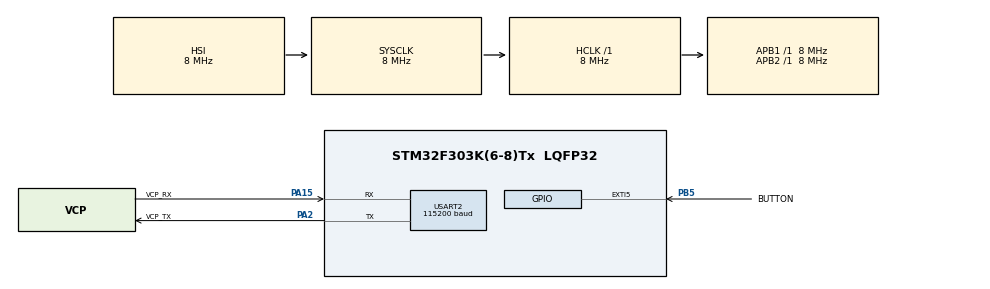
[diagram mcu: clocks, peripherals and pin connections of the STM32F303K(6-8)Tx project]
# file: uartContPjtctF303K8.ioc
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Mcu.Family=STM32F3
Mcu.Name=STM32F303K(6-8)Tx
Mcu.Package=LQFP32
NVIC.EXTI9_5_IRQn=true\:0\:0\:false\:false\:true\:true\:true\:true
NVIC.PriorityGroup=NVIC_PRIORITYGROUP_4
NVIC.USART2_IRQn=true\:0\:0\:false\:false\:true\:true\:true\:true
PA13.GPIO_Label=SWDIO
PA13.Signal=SYS_JTMS-SWDIO
PA14.GPIO_Label=SWCLK
PA14.Signal=SYS_JTCK-SWCLK
PA15.GPIO_Label=VCP_RX
PA15.Mode=Asynchronous
PA15.Signal=USART2_RX
PA2.GPIO_Label=VCP_TX
PA2.Mode=Asynchronous
PA2.Signal=USART2_TX
PB5.GPIO_Label=BUTTON
PB5.GPIO_ModeDefaultEXTI=GPIO_MODE_IT_FALLING
PB5.Signal=GPXTI5
PF0\ /\ OSC_IN.GPIO_Label=MCO
PF0\ /\ OSC_IN.Signal=RCC_OSC_IN
ProjectManager.HeapSize=0x200
ProjectManager.StackSize=0x400
ProjectManager.TargetToolchain=STM32CubeIDE
RCC.AHBFreq_Value=8000000
RCC.APB1Freq_Value=8000000
RCC.APB2Freq_Value=8000000
RCC.CortexFreq_Value=8000000
RCC.HSE_VALUE=8000000
RCC.HSI_VALUE=8000000
RCC.SYSCLKFreq_VALUE=8000000
USART2.BaudRate=115200
USART2.VirtualMode-Asynchronous=VM_ASYNC
board=NUCLEO-F303K8

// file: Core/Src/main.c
/* USER CODE BEGIN Header */
/**
  ******************************************************************************
  * @file           : main.c
  * @brief          : Main program body
  ******************************************************************************
  * @attention
  *
  * Copyright (c) 2025 STMicroelectronics.
  * All rights reserved.
  *
  * This software is licensed under terms that can be found in the LICENSE file
  * in the root directory of this software component.
  * If no LICENSE file comes with this software, it is provided AS-IS.
  *
  ******************************************************************************
  */
/* USER CODE END Header */
#include "main.h"

/* USER CODE BEGIN Includes */
#include <string.h>
/* USER CODE END Includes */

UART_HandleTypeDef huart2;

/* USER CODE BEGIN PV */
uint8_t c=1;
/* USER CODE END PV */

void SystemClock_Config(void);
static void MX_GPIO_Init(void);
static void MX_USART2_UART_Init(void);
/* USER CODE BEGIN PFP */
char* utoa(uint32_t value, char* buffer);
void printUtoa(uint32_t value);
void HAL_GPIO_EXTI_Callback(uint16_t GPIO_Pin);
/* USER CODE END PFP */

int main(void)
{

  /* MCU Configuration--------------------------------------------------------*/

  /* Reset of all peripherals, Initializes the Flash interface and the Systick. */
  HAL_Init();

  /* Configure the system clock */
  SystemClock_Config();

  /* Initialize all configured peripherals */
  MX_GPIO_Init();
  MX_USART2_UART_Init();

  /* Infinite loop */
  /* USER CODE BEGIN WHILE */
  while (1)
  {
	  while(c<=10){
		  printUtoa(c);
		  HAL_UART_Transmit(&huart2, (uint8_t*) "\n", 1, HAL_MAX_DELAY);
		  HAL_Delay(500);
	  }
	  c=1;

	  /* USER CODE END WHILE */

  }
}

void SystemClock_Config(void)
{
  RCC_OscInitTypeDef RCC_OscInitStruct = {0};
  RCC_ClkInitTypeDef RCC_ClkInitStruct = {0};

  /** Initializes the RCC Oscillators according to the specified parameters
  * in the RCC_OscInitTypeDef structure.
  */
  RCC_OscInitStruct.OscillatorType = RCC_OSCILLATORTYPE_HSI;
  RCC_OscInitStruct.HSIState = RCC_HSI_ON;
  RCC_OscInitStruct.HSICalibrationValue = RCC_HSICALIBRATION_DEFAULT;
  RCC_OscInitStruct.PLL.PLLState = RCC_PLL_NONE;
  if (HAL_RCC_OscConfig(&RCC_OscInitStruct) != HAL_OK)
  {
    Error_Handler();
  }

  /** Initializes the CPU, AHB and APB buses clocks
  */
  RCC_ClkInitStruct.ClockType = RCC_CLOCKTYPE_HCLK|RCC_CLOCKTYPE_SYSCLK
                              |RCC_CLOCKTYPE_PCLK1|RCC_CLOCKTYPE_PCLK2;
  RCC_ClkInitStruct.SYSCLKSource = RCC_SYSCLKSOURCE_HSI;
  RCC_ClkInitStruct.AHBCLKDivider = RCC_SYSCLK_DIV1;
  RCC_ClkInitStruct.APB1CLKDivider = RCC_HCLK_DIV1;
  RCC_ClkInitStruct.APB2CLKDivider = RCC_HCLK_DIV1;

  if (HAL_RCC_ClockConfig(&RCC_ClkInitStruct, FLASH_LATENCY_0) != HAL_OK)
  {
    Error_Handler();
  }
}

static void MX_USART2_UART_Init(void)
{

  huart2.Instance = USART2;
  huart2.Init.BaudRate = 115200;
  huart2.Init.WordLength = UART_WORDLENGTH_8B;
  huart2.Init.StopBits = UART_STOPBITS_1;
  huart2.Init.Parity = UART_PARITY_NONE;
  huart2.Init.Mode = UART_MODE_TX_RX;
  huart2.Init.HwFlowCtl = UART_HWCONTROL_NONE;
  huart2.Init.OverSampling = UART_OVERSAMPLING_16;
  huart2.Init.OneBitSampling = UART_ONE_BIT_SAMPLE_DISABLE;
  huart2.AdvancedInit.AdvFeatureInit = UART_ADVFEATURE_NO_INIT;
  if (HAL_UART_Init(&huart2) != HAL_OK)
  {
    Error_Handler();
  }

}

static void MX_GPIO_Init(void)
{
  GPIO_InitTypeDef GPIO_InitStruct = {0};

  /* GPIO Ports Clock Enable */
  __HAL_RCC_GPIOF_CLK_ENABLE();
  __HAL_RCC_GPIOA_CLK_ENABLE();
  __HAL_RCC_GPIOB_CLK_ENABLE();

  /*Configure GPIO pin : BUTTON_Pin */
  GPIO_InitStruct.Pin = BUTTON_Pin;
  GPIO_InitStruct.Mode = GPIO_MODE_IT_FALLING;
  GPIO_InitStruct.Pull = GPIO_NOPULL;
  HAL_GPIO_Init(BUTTON_GPIO_Port, &GPIO_InitStruct);

  /* EXTI interrupt init*/
  HAL_NVIC_SetPriority(EXTI9_5_IRQn, 0, 0);
  HAL_NVIC_EnableIRQ(EXTI9_5_IRQn);

}

/* USER CODE BEGIN 4 */

void HAL_GPIO_EXTI_Callback(uint16_t GPIO_Pin) {
    if (GPIO_Pin == GPIO_PIN_5) {
        // Aquí haces lo que quieras cuando PB5 interrumpe
        c++;
    }
}
char* utoa(uint32_t value, char* buffer) {
    char* ptr = buffer;
    char* ptr1 = buffer;
    char tmp_char;
    uint32_t tmp_value;
    do {
        tmp_value = value;
        value /= 10;
        *ptr++ = '0' + (tmp_value - (value * 10));
    } while (value != 0);

    *ptr-- = '\0';
    while (ptr1 < ptr) {
        tmp_char = *ptr;
        *ptr-- = *ptr1;
        *ptr1++ = tmp_char;
    }

    return buffer;
}
void printUtoa(uint32_t value) {
	static char buffer[12];
    utoa(value, buffer);
    HAL_UART_Transmit(&huart2, (uint8_t*)buffer, strlen(buffer), HAL_MAX_DELAY);
}
/* USER CODE END 4 */

void Error_Handler(void)
{
  __disable_irq();
  while (1)
  {
  }
}
